# RN8XXX_V2 register map
File version: 1.0
Registers are 32-bit, read-write, reset 0x0 unless marked. A register's access mark holds for its fields unless they carry their own. Offsets are from the block's base; [hi:lo] are bit positions; {n}, {i} and the like mark numbered series; 'fields as' and 'values as' point back to an identical list.

## RTC — real time clock
Base 0x4003C000
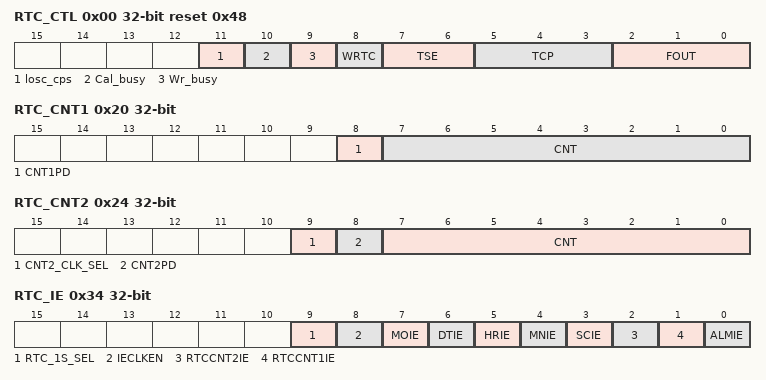
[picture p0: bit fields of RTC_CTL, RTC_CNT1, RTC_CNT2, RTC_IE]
0x00 RTC_CTL reset 0x48 — control register
  [11] losc_cps — losc capacitor configuration
    0=20pF (set losc load capacitor as 20pF); 1=13.6pF (set losc load capacitor as 13.6pF)
  [10] Cal_busy read — RTC calibration busy flag
    0=not_busy (no outstanding RTC calibration); 1=busy (RTC calibration pending)
  [9] Wr_busy read — RTC register set writing busy.content of RTC register set can be changed only when Wr_busy is 0
    0=not_busy (no outstanding RTC register set write, RTC register changable); 1=busy (outstanding RTC register set write pending, RTC register not changable)
  [8] WRTC — RTC register set write enable
    0=disable (RTC register set not writable); 1=enable (RTC register set writable)
  [7:6] TSE — temperature sensor enable
    0=disable (automatic temperature compensation disabled); 1=automatic cyclic temperature compensation enabled; 2=user_mode0 (automatic temperature compensation triggered by setting temperature(temperature set by user)); 3=user_mode1 (automatic temperature compensation triggered by writing temperature(temperature detected by chip))
  [5:3] TCP — temperature compensation period
    0=tcp2s (run TCP every 2 second); 1=tcp10s (run TCP every 10 second); 2=tcp20s (run TCP every 20 second); 3=tcp30s (run TCP every 30 second); 4=tcp1m (run TCP every 1 minute); 5=tcp2m (run TCP every 2 minute); 6=tcp5m (run TCP every 5 minute); 7=tcp10m (run TCP every 10 minute)
  [2:0] FOUT — output frequency
    0=no_output1 (output forbidden); 1=out_1hz (output PLL_1Hz when PLL_MODE=1,output LOSC_1Hz when PLL_MODE=0); 2=out_1/30hz (output at 1/30Hz); 3=out_32768hz (output at 32768Hz); 4=out_16hz (output at 16Hz); 5=out_8hz (output at 8Hz); 6=out_4hz (output at 4Hz)
0x04 RTC_SC — seconds
  [6:0] SC — seconds in BCD format,SC[6:4] standing for 10 seconds,SC[3:0] standing seconds
0x08 RTC_MN — minutes
  [6:0] MN — minutes in BCD format,MN[6:4] standing for 10 minutes,MN[3:0] standing for minutes
0x0C RTC_HR — hours
  [5:0] HR — hours in BCD format,HR[5:4] standing for 10 hours,HR[3:0] standing for hours
0x10 RTC_DT — date
  [5:0] DT — date in BCD format,DT[5:4] standing for 10 date,DT[3:0] standing for date
0x14 RTC_MO — month
  [4:0] MO — month in BCD format,MO[5] standing for 10 month,MO[3:0] standing for month
0x18 RTC_YR — year
  [7:0] YR — year in BCD format,YR[7:4] standing for 10 year,YR[3:0] standing for year
0x1C RTC_DW — day of the week
  [2:0] DW
    0=sunday (today is sunday); 1=monday (today is monday); 2=tuesday (today is tuesday); 3=wednesday (today is wednesday); 4=thursday (today is thursday); 5=friday (today is friday); 6=saturday (today is saturday)
0x20 RTC_CNT1 — RTC counter1
  [8] CNT1PD — CNT1 ON/OFF control
    0=ON (counter1 on); 1=OFF (counter1 off, reset the counter value and restart)
  [7:0] CNT — set counter1 flag when every (CNT+1) seconds
0x24 RTC_CNT2 — RTC counter2
  [9] CNT2_CLK_SEL — CNT2 CLK selection
    0=32768hz (CNT2 CLK select 32768hz); 1=RCL (CNT2 CLK select RCL)
  [8] CNT2PD — CNT2 ON/OFF control
    0=ON (counter2 on); 1=OFF (counter2 off, reset the counter value and restart)
  [7:0] CNT — set counter2 flag when every (CNT+1)/256 seconds
0x28 RTC_SCA — alarm seconds
  [6:0] SCA — alarm seconds in BCD format,SCA[6:4] standing for 10 seconds,SCA[3:0] standing for seconds
0x2C RTC_MNA — alarm minitues
  [6:0] MNA — alarm minitues in BCD format,MNA[6:4] standing for 10 minitues,MNA[3:0] standing for minitues
0x30 RTC_HRA — alarm hours
  [5:0] HRA — alarm hours in BCD format,MNA[5:4] standing for 10 hours,MNA[3:0] standing for hours
0x34 RTC_IE — interrupt enables
  [9] RTC_1S_SEL — RTC_1S clock source selection
    0=PLL_1HZ (clock source is PLL_1Hz); 1=RTC_1HZ (clock is from RTC 1Hz)
  [8] IECLKEN — interrupt clock enable.enabled when any bit of RTC_IE[8:0] is high
    0=disable (clock disabled gracefully); 1=enable (clock enabled)
  [7] MOIE — month interrupt enable
    0=disable (do not generate interrupt on month event); 1=enable (generate interrupt on month event)
  [6] DTIE — date interrupt enable
    0=disable (do not generate interrupt on date event); 1=enable (generate interrupt on date event)
  [5] HRIE — hour interrupt enable
    0=disable (do not generate interrupt on hour event); 1=enable (generate interrupt on hour event)
  [4] MNIE — minute interrupt enable
    0=disable (do not generate interrupt on minute event); 1=enable (generate interrupt on minute event)
  [3] SCIE — sencond interrupt enable
    0=disable (do not generate interrupt on sencond event); 1=enable (generate interrupt on sencond event)
  [2] RTCCNT2IE — counter2 interrupt enable
    0=disable (do not generate interrupt on counter2 event); 1=enable (generate interrupt on counter2 event)
  [1] RTCCNT1IE — counter1 interrupt enable
    0=disable (do not generate interrupt on counter1 event); 1=enable (generate interrupt on counter1 event)
  [0] ALMIE — alarm interrupt enable
    0=disable (do not generate interrupt on alarm event); 1=enable (generate interrupt on alarm event)
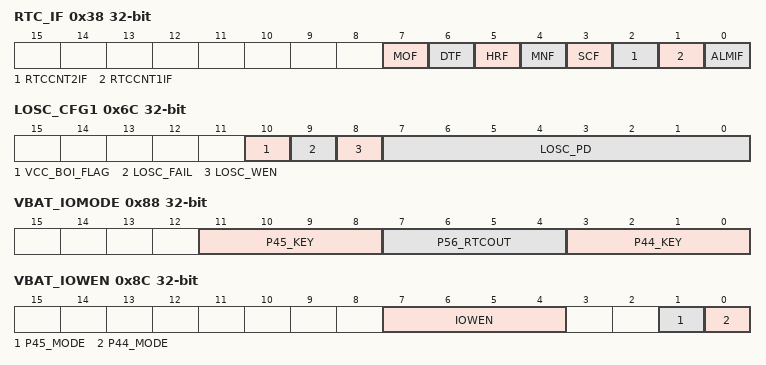
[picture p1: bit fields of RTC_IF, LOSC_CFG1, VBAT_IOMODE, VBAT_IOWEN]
0x38 RTC_IF — RTC interrupt sign register
  [7] MOF write-1-clears — month event flag
    0=not_pending (no outstanding month event); 1=pending (month event pending)
  [6] DTF write-1-clears — date event flag
    0=not_pending (no outstanding date event); 1=pending (date event pending)
  [5] HRF write-1-clears — hour event flag
    0=not_pending (no outstanding hour event); 1=pending (hour event pending)
  [4] MNF write-1-clears — minute event flag
    0=not_pending (no outstanding minute event); 1=pending (minute event pending)
  [3] SCF write-1-clears — sencond event flag
    0=not_pending (no outstanding sencond event); 1=pending (sencond event pending)
  [2] RTCCNT2IF write-1-clears — counter2 event flag
    0=not_pending (no outstanding counter2 event); 1=pending (counter2 event pending)
  [1] RTCCNT1IF write-1-clears — counter1 event flag
    0=not_pending (no outstanding counter1 event); 1=pending (counter1 event pending)
  [0] ALMIF write-1-clears — alarm event flag
    0=not_pending (no outstanding alarm event); 1=pending (alarm event pending)
0x3C RTC_TEMP — current chip temperature
  [14:0] TEMP — current chip temperature.TEMP[9] for sign, TEMP[8:2] for integer part,TEMP[1:0] for decimal part
0x48 RTC_DOTA0
  [12:0] DOTA0
0x6C LOSC_CFG1 — LOSC configurating regerster
  [10] VCC_BOI_FLAG ro — VCC running flag
    0=normal (vcc run normally); 1=failed (vcc once been powered down)
  [9] LOSC_FAIL ro — LOSC running flag
    0=normal (LOSC run normally); 1=failed (LOSC once have failed)
  [8] LOSC_WEN — enable writing LOSC enable bits
    0=disable LOSC; 1=enable LOSC
  [7:0] LOSC_PD — LOSC enable
    168=disable LOSC; ?=enable LOSC
0x88 VBAT_IOMODE — IO mode in VBAT area
  [11:8] P45_KEY — mode of P45
    5=enable cases open recording event; 14=disable cases open recording event (disable and clear 0x90~0xBC)
  [7:4] P56_RTCOUT — mode of P56
    10=enable RTC_OUT
  [3:0] P44_KEY — reserved
    values as P45_KEY
0x8C VBAT_IOWEN — RTC IO mode selection
  [7:4] IOWEN — RTC_IOEN write protel password
  [1] P45_MODE — P45 mode setting
    0=record 0 (record the two earliest press key event); 1=record 1 (record the two lastest press key event)
  [0] P44_MODE — P44 mode setting
    values as P45_MODE
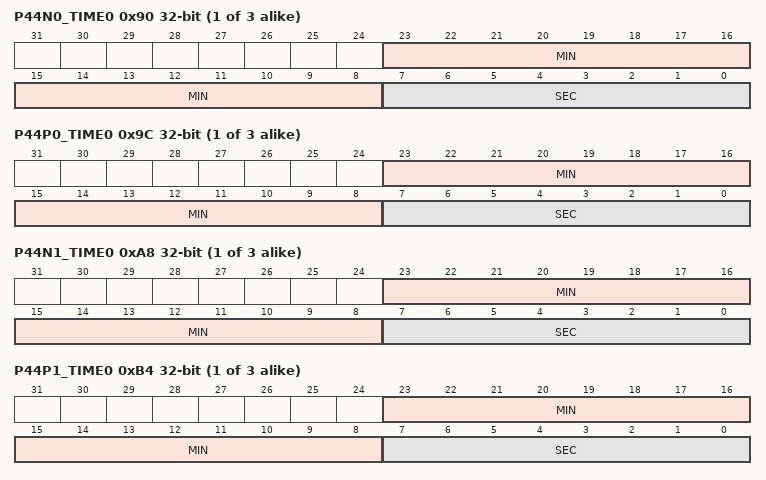
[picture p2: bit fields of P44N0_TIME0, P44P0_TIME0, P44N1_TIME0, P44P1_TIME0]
{0x90+4i} P44N0_TIME{i} (i=0..2) — P44N0_TIME{i} 1st falling edge timestamp
  [23:8] MIN ro — minute of timestamp
  [7:0] SEC ro — seconds of timestamp
{0x9C+4i} P44P0_TIME{i} (i=0..2) — P44P0_TIME{i} 1st rising edge timestamp
  fields as P44N0_TIME0
{0xA8+4i} P44N1_TIME{i} (i=0..2) — P44N1_TIME{i} 2nd falling edge timestamp
  fields as P44N0_TIME0
{0xB4+4i} P44P1_TIME{i} (i=0..2) — P44P1_TIME{i} 2nd rising edge timestamp
  fields as P44N0_TIME0
0xCC RTC_CALPS — Password register for RTC calibration registers
  [7:0] CALPS — password, only when 0xa8 was writen to it, RTC calibration registers can be set
0xD0 RTC_CAL_T0 — RTC calibration register T0
  [7:0] CAL — to calibrate RTC for 0.25ppm per bit when temprature is lower than -30 degree
0xD4 RTC_CAL_T1 — RTC calibration register T1
  [7:0] CAL — to calibrate RTC for 0.25ppm per bit when temprature is between -30 and -20 degree
0xD8 RTC_CAL_T2 — RTC calibration register T2
  [7:0] CAL — to calibrate RTC for 0.25ppm per bit when temprature is between -20 and -10 degree
0xDC RTC_CAL_T3 — RTC calibration register T3
  [7:0] CAL — to calibrate RTC for 0.25ppm per bit when temprature is between -10 and 0 degree
0xE0 RTC_CAL_T4 — RTC calibration register T4
  [7:0] CAL — to calibrate RTC for 0.25ppm per bit when temprature is between 0 and 10 degree
{0xD0+4i} RTC_CAL_T{i} (i=5..8) — RTC calibration register T{i}
  [7:0] CAL — to calibrate RTC for 0.25ppm per bit when temprature is between {10i-15} and {10i-5} degree
0xF4 RTC_CAL_T9 — RTC calibration register T9
  [7:0] CAL — to calibrate RTC for 0.25ppm per bit when temprature is higher than 75 degree
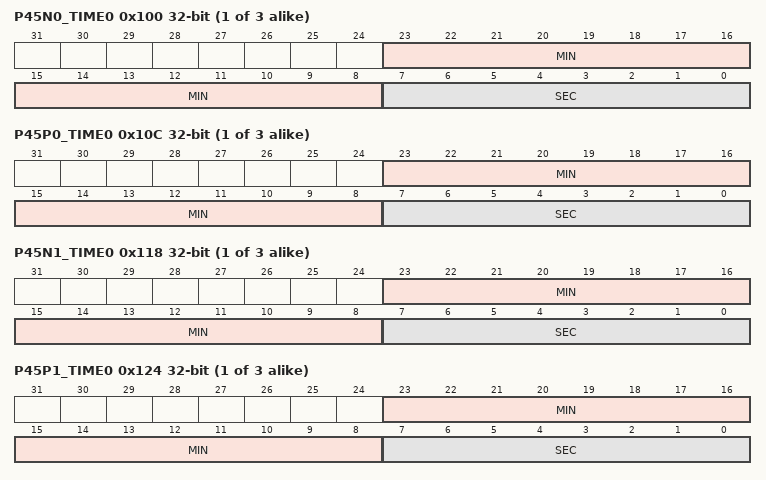
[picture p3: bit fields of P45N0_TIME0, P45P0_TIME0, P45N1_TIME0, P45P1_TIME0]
{0x100+4i} P45N0_TIME{i} (i=0..2) — P45N0_TIME{i} 1st falling edge timestamp
  fields as P44N0_TIME0
{0x10C+4i} P45P0_TIME{i} (i=0..2) — P45P0_TIME{i} 1st rising edge timestamp
  fields as P44N0_TIME0
{0x118+4i} P45N1_TIME{i} (i=0..2) — P45N1_TIME{i} 2nd falling edge timestamp
  fields as P44N0_TIME0
{0x124+4i} P45P1_TIME{i} (i=0..2) — P45P1_TIME{i} 2nd rising edge timestamp
  fields as P44N0_TIME0
